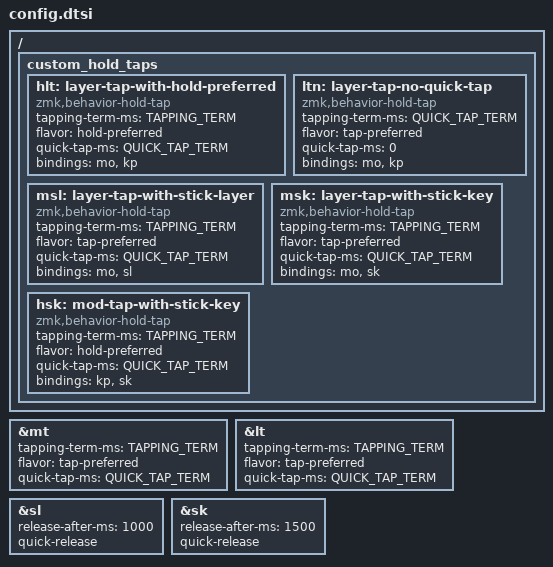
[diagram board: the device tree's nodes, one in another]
/*
*
* Copyright (c) 2025 Ryan Luckie
* SPDX-License-Identifier: MIT
*
*/
 // Layers

#define ALPHA1 0

#define CAMEL_CASE 1
#define SNAKE_CASE 2
#define CONST_CASE 3
#define KEBAB_CASE 4
#define SLASH_CASE 5
#define SPACING 6
#define CASE_A1 7
#define CPLK_A1 8

#define ALPHA2 9

#define NUM 10
#define SYM 11

#define SEN_CASE 12
#define CCEDIL 13
#define SFT_A2 14
#define CASE_A2 15
#define CASE_CCEDIL 16

#define SHRT 17
#define MEHS 18

#define PLAIN1 19
#define PLAIN2 20
#define SFT_PLAIN2 21
#define ALTREP2 22

#define NAV 23

#define NUM_CP 24
#define SYM_CP 25

#define MED 26
#define NAV_CP 27

#define TEXT 28
#define FUN 29
#define SMART 30

// Settings

#define COMBO_TERM 30
#define TAPPING_TERM 250
#define QUICK_TAP_TERM 175
#define ADAPTIVE_KEY_TIMEOUT 2000


/*                KEY POSITIONS

  ╭─────────────────────────┬─────────────────────────╮
  │ LT5 LT4 LT3 LT2 LT1 LT0 │ RT0 RT1 RT2 RT3 RT4 RT5 │
  │ LM5 LM4 LM3 LM2 LM1 LM0 │ RM0 RM1 RM2 RM3 RM4 RM5 │
  │ LB5 LB4 LB3 LB2 LB1 LB0 │ RB0 RB1 RB2 RB3 RB4 RB5 │
  ╰───────────╮ LH2 LH1 LH0 │ RH0 RH1 RH2 ╭───────────╯
              ╰─────────────┴─────────────╯
  ╭─────────────────────────┬─────────────────────────╮
  │   0   1   2   3   4   5 │   6   7   8   9  10  11 │
  │  12  13  14  15  16  17 │  18  19  20  21  22  23 │
  │  24  25  26  27  28  29 │  30  31  32  33  34  35 │
  ╰───────────╮  36  37  38 │  39  40  41 ╭───────────╯
              ╰─────────────┴─────────────╯
*/


&mt {
    tapping-term-ms = <TAPPING_TERM>;
    flavor = "tap-preferred";
    quick-tap-ms = <QUICK_TAP_TERM>;
};

&lt {
    tapping-term-ms = <TAPPING_TERM>;
    flavor = "tap-preferred";
    quick-tap-ms = <QUICK_TAP_TERM>;
};

&sl {
    release-after-ms = <1000>;
    quick-release;
};

&sk {
    release-after-ms = <1500>;
    quick-release;
};

/ {
    custom_hold_taps {

        hlt: layer-tap-with-hold-preferred {
            compatible = "zmk,behavior-hold-tap";
            #binding-cells = <2>;
            tapping-term-ms = <TAPPING_TERM>;
            flavor = "hold-preferred";
            quick-tap-ms = <QUICK_TAP_TERM>;
            bindings = <&mo>, <&kp>;
        };

        ltn: layer-tap-no-quick-tap {
            compatible = "zmk,behavior-hold-tap";
            #binding-cells = <2>;
            tapping-term-ms = <QUICK_TAP_TERM>;
            flavor = "tap-preferred";
            quick-tap-ms = <0>;
            bindings = <&mo>, <&kp>;
        };

        msl: layer-tap-with-stick-layer {
            compatible = "zmk,behavior-hold-tap";
            #binding-cells = <2>;
            tapping-term-ms = <TAPPING_TERM>;
            flavor = "tap-preferred";
            quick-tap-ms = <QUICK_TAP_TERM>;
            bindings = <&mo>, <&sl>;
        };

        msk: layer-tap-with-stick-key {
            compatible = "zmk,behavior-hold-tap";
            #binding-cells = <2>;
            tapping-term-ms = <TAPPING_TERM>;
            flavor = "tap-preferred";
            quick-tap-ms = <QUICK_TAP_TERM>;
            bindings = <&mo>, <&sk>;
        };

        hsk: mod-tap-with-stick-key {
            compatible = "zmk,behavior-hold-tap";
            #binding-cells = <2>;
            tapping-term-ms = <TAPPING_TERM>;
            flavor = "hold-preferred";
            quick-tap-ms = <QUICK_TAP_TERM>;
            bindings = <&kp>, <&sk>;
        };

    };
};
